# LPC122x register map
File version: 2
Registers are 32-bit, read-write, reset 0x0 unless marked. A register's access mark holds for its fields unless they carry their own. Offsets are from the block's base; [hi:lo] are bit positions; {n}, {i} and the like mark numbered series; 'fields as' and 'values as' point back to an identical list.

## UART1 — Product name title=UM10441 Chapter title=LPC122x UART1 Modification date=2/3/2011 Major revision=0 Minor revision=17
Base 0x4000C000
0x00 RBR ro read-modifies — Receiver Buffer Register. Contains the next received character to be read.
  [7:0] RBR — The UART Receiver Buffer Register contains the oldest received byte in the UART RX FIFO.
0x00 THR wo (alternate view of RBR) — Transmit Holding Register. The next character to be transmitted is written here.
  [7:0] THR — Writing to the UART Transmit Holding Register causes the data to be stored in the UART transmit FIFO. The byte will be sent when it reaches the bottom of the FIFO and the transmitter is available.
0x00 DLL reset 0x1 (alternate view of RBR) — Divisor Latch LSB. Least significant byte of the baud rate divisor value. The full divisor is used to generate a baud rate from the fractional rate divider.
  [7:0] DLLSB — The UART Divisor Latch LSB Register, along with the DLM register, determines the baud rate of the UART.
0x04 DLM — Divisor Latch MSB. Most significant byte of the baud rate divisor value. The full divisor is used to generate a baud rate from the fractional rate divider. (DLAB = 1).
  [7:0] DLMSB — The UART Divisor Latch MSB Register, along with the DLL register, determines the baud rate of the UART.
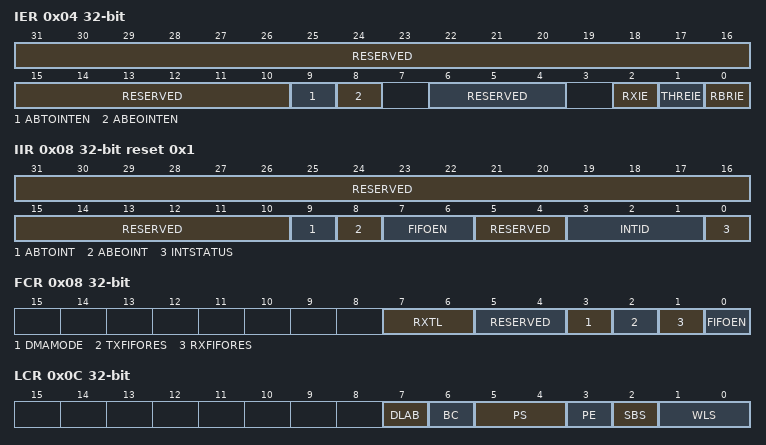
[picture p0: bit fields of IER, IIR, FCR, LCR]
0x04 IER (alternate view of DLM) — Interrupt Enable Register. Contains individual interrupt enable bits for the 7 potential UART interrupts. (DLAB = 0)
  [31:10] RESERVED — Reserved, user software should not write ones to reserved bits. The value read from a reserved bit is not defined.
  [9] ABTOINTEN — Enables the auto-baud time-out interrupt.
    0=DISABLE (Disable auto-baud time-out Interrupt.); 1=ENABLE (Enable auto-baud time-out Interrupt.)
  [8] ABEOINTEN — Enables the end of auto-baud interrupt.
    0=DISABLE (Disable end of auto-baud Interrupt.); 1=ENABLE (Enable end of auto-baud Interrupt.)
  [6:4] RESERVED — Reserved, user software should not write ones to reserved bits. The value read from a reserved bit is not defined.
  [2] RXIE — RX Line Interrupt Enable. Enables the UART RX line status interrupts. The status of this interrupt can be read from LSR[4:1].
    0=DISABLE (Disable the RX line status interrupts.); 1=ENABLE (Enable the RX line status interrupts.)
  [1] THREIE — THRE Interrupt Enable. Enables the THRE interrupt for UART. The status of this interrupt can be read from LSR[5].
    0=DISABLE (Disable the THRE interrupts.); 1=ENABLE (Enable the THRE interrupts.)
  [0] RBRIE — RBR Interrupt Enable. Enables the Receive Data Available interrupt for UART. It also controls the Character Receive Time-out interrupt.
    0=DISABLE (Disable the RDA interrupts.); 1=ENABLE (Enable the RDA interrupts.)
0x08 IIR ro reset 0x1 — Interrupt ID Register. Identifies which interrupt(s) are pending.
  [31:10] RESERVED — Reserved, user software should not write ones to reserved bits. The value read from a reserved bit is not defined.
  [9] ABTOINT — Auto-baud time-out interrupt. True if auto-baud has timed out and interrupt is enabled.
  [8] ABEOINT — End of auto-baud interrupt. True if auto-baud has finished successfully and interrupt is enabled.
  [7:6] FIFOEN — FIFO enable. These bits are equivalent to FCR[0].
  [5:4] RESERVED — Reserved, user software should not write ones to reserved bits. The value read from a reserved bit is not defined.
  [3:1] INTID — Interrupt identification. IER[3:1] identifies an interrupt corresponding to the UART RX FIFO. All other combinations of IER[3:1] not listed below are reserved (000,100,101,111).
    3=RECEIVE_LINE_S (1 - Receive Line Status (RLS).); 2=RECEIVE_DATA_AV (2a - Receive Data Available (RDA).); 6=CHARACTER_TIME_ (2b - Character Time-out Indicator (CTI).); 1=THRE_INTERRUPT (3 - THRE Interrupt.)
  [0] INTSTATUS — Interrupt status. Note that IIR[0] is active low. The pending interrupt can be determined by evaluating IIR[3:1].
    0=PENDING (At least one interrupt is pending.); 1=NO_INTERRUPT_IS_PEND (No interrupt is pending.)
0x08 FCR wo (alternate view of IIR) — FIFO Control Register. Controls UART FIFO usage and modes.
  [7:6] RXTL — RX Trigger Level. These two bits determine how many receiver UART FIFO characters must be written before an interrupt is activated.
    0=TRIGGER_LEVEL_0 (Trigger level 0 (1 character or 0x01).); 1=TRIGGER_LEVEL_1 (Trigger level 1 (4 characters or 0x04).); 2=TRIGGER_LEVEL_2 (Trigger level 2 (8 characters or 0x08).); 3=TRIGGER_LEVEL_3 (Trigger level 3 (14 characters or 0x0E).)
  [5:4] RESERVED — Reserved, user software should not write ones to reserved bits. The value read from a reserved bit is not defined.
  [3] DMAMODE — DMA Mode Select. When the FIFO enable bit (bit 0 of this register) is set, this bit selects the DMA mode. See Section 10.5.6.1.
    0=DMA_NOT_USED_; 1=DMA_MODE_ENABLED_
  [2] TXFIFORES — TX FIFO Reset
    0=NO_IMPACT_ON_EITHER_ (No impact on either of UART FIFOs.); 1=CLEAR (Writing a logic 1 to FCR[2] will clear all bytes in UART TX FIFO, reset the pointer logic. This bit is self-clearing.)
  [1] RXFIFORES — RX FIFO Reset
    0=NO_IMPACT_ON_EITHER_ (No impact on either of UART FIFOs.); 1=CLEAR (Writing a logic 1 to FCR[1] will clear all bytes in UART RX FIFO, reset the pointer logic. This bit is self-clearing.)
  [0] FIFOEN — FIFO Enable
    0=DISABLED (UART FIFOs are disabled. Must not be used in the application.); 1=ENABLED (Active high enable for both UART RX and TX FIFOs and FCR[7:1] access. This bit must be set for proper UART operation. Any transition on this bit will automatically clear the UART FIFOs.)
0x0C LCR — Line Control Register. Contains controls for frame formatting and break generation.
  [7] DLAB — Divisor Latch Access Bit (DLAB)
    0=DISABLE_ACCESS_TO_DI (Disable access to Divisor Latches.); 1=ENABLE_ACCESS_TO_DIV (Enable access to Divisor Latches.)
  [6] BC — Break Control
    0=DISABLE_BREAK_TRANSM (Disable break transmission.); 1=ENABLE_BREAK_TRANSMI (Enable break transmission. Output pin UART TXD is forced to logic 0 when LCR[6] is active high.)
  [5:4] PS — Parity Select
    0=ODD_PARITY_NUMBER_O (Odd parity. Number of 1s in the transmitted character and the attached parity bit will be odd.); 1=EVEN_PARITY_NUMBER_ (Even Parity. Number of 1s in the transmitted character and the attached parity bit will be even.); 2=FORCED_1_STICK_PARIT (Forced 1 stick parity.); 3=FORCED_0_STICK_PARIT (Forced 0 stick parity.)
  [3] PE — Parity Enable
    0=DISABLE_PARITY_GENER (Disable parity generation and checking.); 1=ENABLE_PARITY_GENERA (Enable parity generation and checking.)
  [2] SBS — Stop Bit Select
    0=1_STOP_BIT_; 1=2_STOP_BITS_ (2 stop bits (1.5 if LCR[1:0]=00).)
  [1:0] WLS — Word Length Select
    {v}={v+5}_BIT_CHARACTER_LENG ({v+5}-bit character length.) (v=0..3)
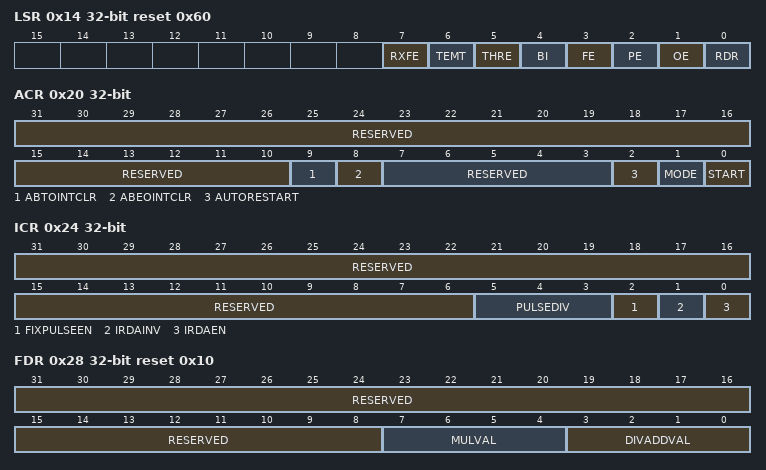
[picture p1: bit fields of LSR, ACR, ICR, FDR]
0x14 LSR ro reset 0x60 — Line Status Register. Contains flags for transmit and receive status, including line errors.
  [7] RXFE — Error in RX FIFO. LSR[7] is set when a character with a RX error such as framing error, parity error or break interrupt, is loaded into the RBR. This bit is cleared when the LSR register is read and there are no subsequent errors in the UART FIFO.
    0=NO_ERROR (RBR contains no UART RX errors or FCR[0]=0.); 1=ERROR (UART RBR contains at least one UART RX error.)
  [6] TEMT — Transmitter Empty. TEMT is set when both THR and TSR are empty; TEMT is cleared when either the TSR or the THR contain valid data.
    0=DATA (THR and/or the TSR contains valid data.); 1=EMPTY (THR and the TSR are empty.)
  [5] THRE — Transmitter Holding Register Empty. THRE is set immediately upon detection of an empty UART THR and is cleared on a THR write.
    0=DATA (THR contains valid data.); 1=THR_IS_EMPTY_
  [4] BI — Break Interrupt. When RXD1 is held in the spacing state (all zeros) for one full character transmission (start, data, parity, stop), a break interrupt occurs. Once the break condition has been detected, the receiver goes idle until RXD1 goes to marking state (all ones). An LSR read clears this status bit. The time of break detection is dependent on FCR[0]. Note: The break interrupt is associated with the character at the top of the UART RBR FIFO.
    0=INACTIVE (Break interrupt status is inactive.); 1=ACTIVE (Break interrupt status is active.)
  [3] FE — Framing Error. When the stop bit of a received character is a logic 0, a framing error occurs. An LSR read clears LSR[3]. The time of the framing error detection is dependent on FCR0. Upon detection of a framing error, the RX will attempt to resynchronize to the data and assume that the bad stop bit is actually an early start bit. However, it cannot be assumed that the next received byte will be correct even if there is no Framing Error. Note: A framing error is associated with the character at the top of the UART RBR FIFO.
    0=INACTIVE (Framing error status is inactive.); 1=ACTIVE (Framing error status is active.)
  [2] PE — Parity Error. When the parity bit of a received character is in the wrong state, a parity error occurs. An LSR read clears LSR[2]. Time of parity error detection is dependent on FCR[0]. Note: A parity error is associated with the character at the top of the UART RBR FIFO.
    0=INACTIVE (Parity error status is inactive.); 1=ACTIVE (Parity error status is active.)
  [1] OE — Overrun Error. The overrun error condition is set as soon as it occurs. An LSR read clears LSR[1]. LSR[1] is set when UART RSR has a new character assembled and the UART RBR FIFO is full. In this case, the UART RBR FIFO will not be overwritten and the character in the UART RSR will be lost.
    0=INACTIVE (Overrun error status is inactive.); 1=ACTIVE (Overrun error status is active.)
  [0] RDR — Receiver Data Ready. LSR[0] is set when the RBR holds an unread character and is cleared when the UART RBR FIFO is empty.
    0=RBR_IS_EMPTY_; 1=RBR_CONTAINS_VALID_D (RBR contains valid data.)
0x1C SCR — Scratch Pad Register. Eight-bit temporary storage for software.
  [7:0] Pad — A readable, writable byte.
0x20 ACR — Auto-baud Control Register. Contains controls for the auto-baud feature.
  [31:10] RESERVED — Reserved, user software should not write ones to reserved bits. The value read from a reserved bit is not defined.
  [9] ABTOINTCLR — Auto-baud time-out interrupt clear bit (write only accessible).
    0=NOIMPACT (Writing a 0 has no impact.); 1=CLEAR (Writing a 1 will clear the corresponding interrupt in the IIR.)
  [8] ABEOINTCLR — End of auto-baud interrupt clear bit (write only accessible).
    values as ABTOINTCLR
  [7:3] RESERVED — Reserved, user software should not write ones to reserved bits. The value read from a reserved bit is not defined.
  [2] AUTORESTART — Auto start mode
    0=NORESTART; 1=RESTART_IN_CASE_OF_T (Restart in case of time-out (counter restarts at next UART RX falling edge))
  [1] MODE — Auto-baud mode select bit.
    0=MODE_0_; 1=MODE_1_
  [0] START — This bit is automatically cleared after auto-baud completion.
    0=AUTO_BAUD_STOP (Auto-baud stop (auto-baud is not running).); 1=AUTO_BAUD_START (Auto-baud start (auto-baud is running). Auto-baud run bit. This bit is automatically cleared after auto-baud completion.)
0x24 ICR — IrDA Control Register. Enables and configures the IrDA mode.
  [31:6] RESERVED — Reserved, user software should not write ones to reserved bits. The value read from a reserved bit is not defined.
  [5:3] PULSEDIV — Configures the pulse when FixPulseEn = 1.
    0=2_TPCLK (2 x TPCLK); 1=4_TPCLK (4 xTPCLK); 2=8_TPCLK (8 x TPCLK); 3=16_TPCLK (16 x TPCLK); 4=32_TPCLK (32 x TPCLK); 5=64_TPCLK (64 x TPCLK); 6=128_TPCLK (128x TPCLK); 7=256_TPCLK (256 x TPCLK)
  [2] FIXPULSEEN — IrDA fixed pulse width mode.
    0=DISABLED (IrDA fixed pulse width mode disabled.); 1=ENABLED (IrDA fixed pulse width mode enabled.)
  [1] IRDAINV — IrDA input polarity.
    0=NOTINVERTED (The serial input is not inverted.); 1=INVERTED (The serial input is inverted. This has no effect on the serial output.)
  [0] IRDAEN — IrDA mode enable.
    0=DISABLED (IrDA mode on UARTn is disabled, UARTn acts as a standard UART.); 1=ENABLED (IrDA mode on UARTn is enabled.)
0x28 FDR reset 0x10 — Fractional Divider Register. Generates a clock input for the baud rate divider.
  [31:8] RESERVED — Reserved, user software should not write ones to reserved bits. The value read from a reserved bit is not defined.
  [7:4] MULVAL — Baud-rate pre-scaler multiplier value. This field must be greater or equal 1 for UARTn to operate properly, regardless of whether the fractional baud-rate generator is used or not.
  [3:0] DIVADDVAL — Baud-rate generation pre-scaler divisor value. If this field is 0, fractional baud-rate generator will not impact the UARTn baudrate.
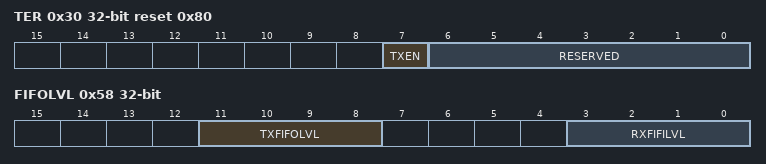
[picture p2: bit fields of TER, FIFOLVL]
0x30 TER reset 0x80 — Transmit Enable Register. Turns off UART transmitter for use with software flow control.
  [7] TXEN — When this bit is 1, as it is after a Reset, data written to the THR is output on the TXD pin as soon as any preceding data has been sent. If this bit cleared to 0 while a character is being sent, the transmission of that character is completed, but no further characters are sent until this bit is set again. In other words, a 0 in this bit blocks the transfer of characters from the THR or TX FIFO into the transmit shift register. Software can clear this bit when it receives an XOFF character (DC3). Software can set this bit again when it receives an XON (DC1) character.
  [6:0] RESERVED — Reserved, user software should not write ones to reserved bits. The value read from a reserved bit is not defined.
0x58 FIFOLVL ro — FIFO Level register. Provides the current fill levels of the transmit and receive FIFOs.
  [11:8] TXFIFOLVL — Reflects the current level of the UART transmitter FIFO. 0 = empty, 0xF = FIFO full.
  [3:0] RXFIFILVL — Reflects the current level of the UART receiver FIFO. 0 = empty, 0xF = FIFO full.
